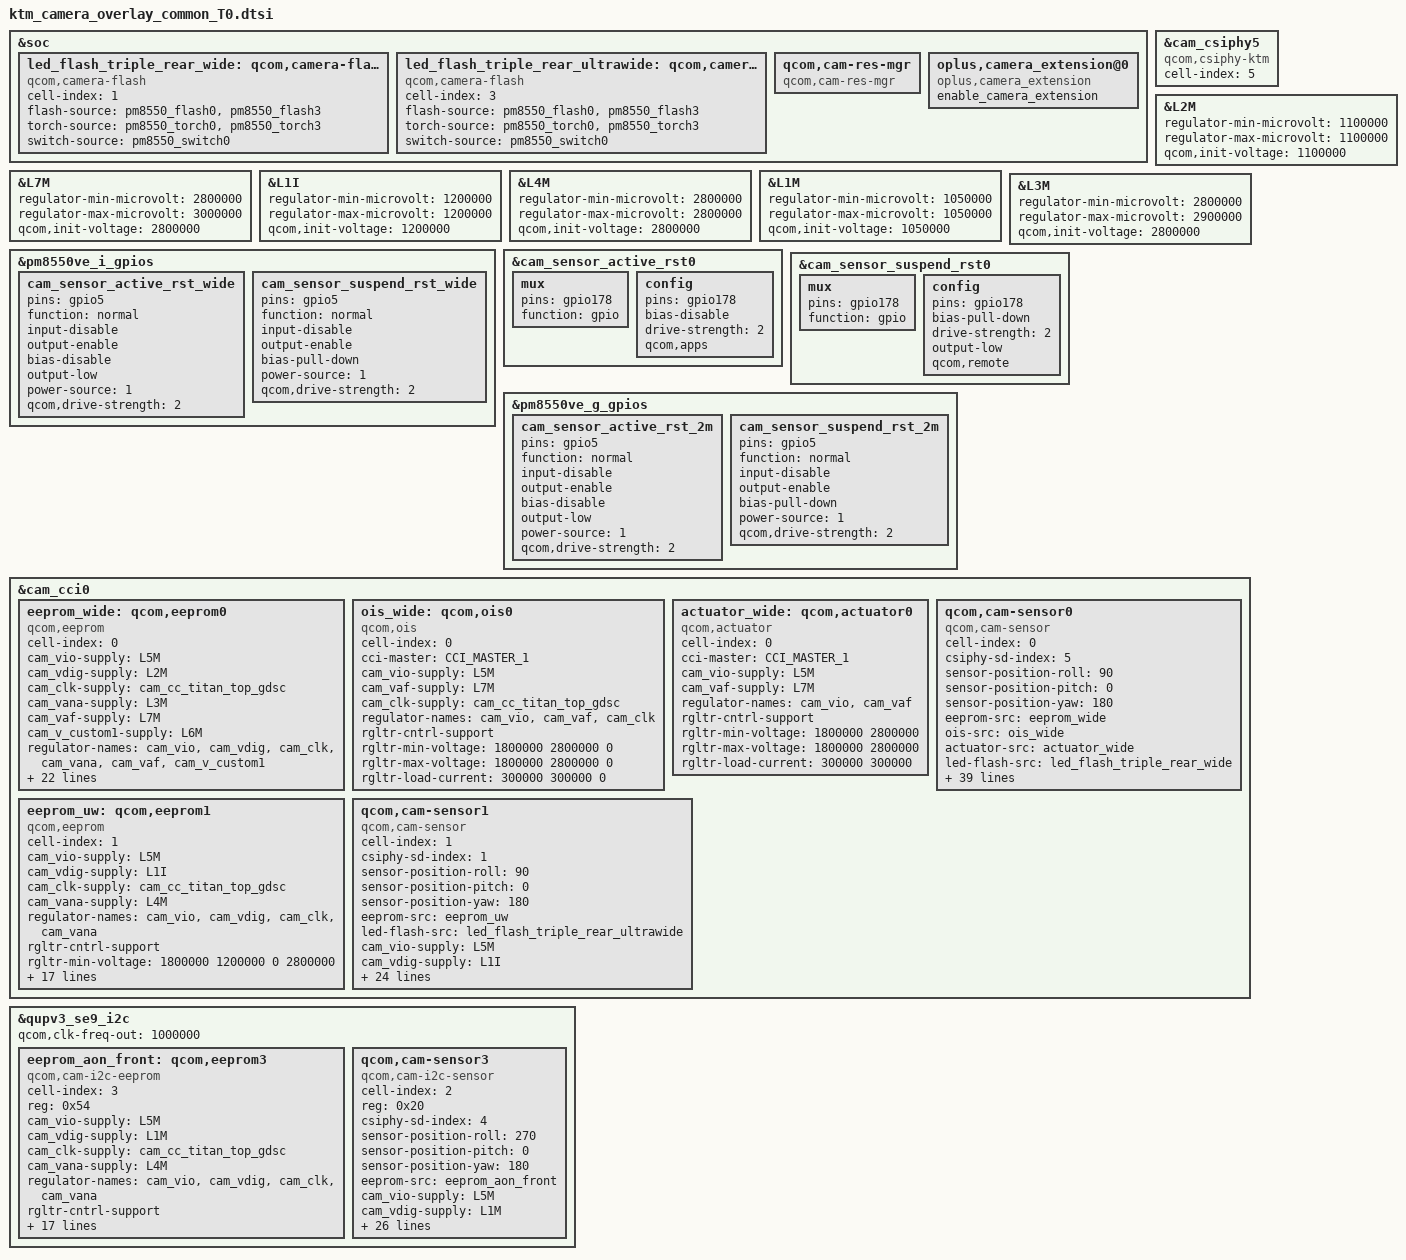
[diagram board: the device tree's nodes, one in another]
#include <dt-bindings/msm-camera.h>
#include "ftm_camera_settings.dtsi"

&soc {
	led_flash_triple_rear_wide: qcom,camera-flash1 {
		cell-index = <1>;
		compatible = "qcom,camera-flash";
		flash-source = <&pm8550_flash0 &pm8550_flash3>;
		torch-source = <&pm8550_torch0 &pm8550_torch3>;
		switch-source = <&pm8550_switch0>;
		status = "ok";
	};

	led_flash_triple_rear_ultrawide: qcom,camera-flash3 {
		cell-index = <3>;
		compatible = "qcom,camera-flash";
		flash-source = <&pm8550_flash0 &pm8550_flash3>;
		torch-source = <&pm8550_torch0 &pm8550_torch3>;
		switch-source = <&pm8550_switch0>;
		status = "ok";
	};

	qcom,cam-res-mgr {
		compatible = "qcom,cam-res-mgr";
		status = "ok";
	};

	oplus,camera_extension@0 {
		compatible = "oplus,camera_extension";
		enable_camera_extension;
		status = "ok";
	};
};

&cam_csiphy5{
	cell-index = <5>;
	compatible = "qcom,csiphy-ktm", "qcom,csiphy";
};

&L2M {
  regulator-min-microvolt = <1100000>;
  regulator-max-microvolt = <1100000>;
  qcom,init-voltage = <1100000>;
};

&L7M {
  regulator-min-microvolt = <2800000>;
  regulator-max-microvolt = <3000000>;
  qcom,init-voltage = <2800000>;
};

&L1I {
  regulator-min-microvolt = <1200000>;
  regulator-max-microvolt = <1200000>;
  qcom,init-voltage = <1200000>;
};

&L4M {
  regulator-min-microvolt = <2800000>;
  regulator-max-microvolt = <2800000>;
  qcom,init-voltage = <2800000>;
};

&L1M {
  regulator-min-microvolt = <1050000>;
  regulator-max-microvolt = <1050000>;
  qcom,init-voltage = <1050000>;
};

&L3M {
  regulator-min-microvolt = <2800000>;
  regulator-max-microvolt = <2900000>;
  qcom,init-voltage = <2800000>;
};


&pm8550ve_i_gpios {
	cam_sensor_active_rst_wide: cam_sensor_active_rst_wide {
		pins = "gpio5";
		function = "normal";
		input-disable;
		output-enable;
		bias-disable;
		output-low;
		power-source = <1>;
		qcom,drive-strength = <2>;
	};

	cam_sensor_suspend_rst_wide: cam_sensor_suspend_rst_wide {
		pins = "gpio5";
		function = "normal";
		input-disable;
		output-enable;
		bias-pull-down;
		power-source = <1>;
		qcom,drive-strength = <2>;
	};
};

&cam_sensor_active_rst0 {
	mux {
		pins = "gpio178";
		function = "gpio";
	};

	config {
		pins = "gpio178";
		bias-disable; /* No PULL */
		drive-strength = <2>; /* 2 MA */
		qcom,apps;
	};
};

&cam_sensor_suspend_rst0 {
	mux {
		pins = "gpio178";
		function = "gpio";
	};

	config {
		pins = "gpio178";
		bias-pull-down; /* PULL DOWN */
		drive-strength = <2>; /* 2 MA */
		output-low;
		qcom,remote;
	};
};

&pm8550ve_g_gpios {
	cam_sensor_active_rst_2m: cam_sensor_active_rst_2m {
		pins = "gpio5";
		function = "normal";
		input-disable;
		output-enable;
		bias-disable;
		output-low;
		power-source = <1>;
		qcom,drive-strength = <2>;
	};

	cam_sensor_suspend_rst_2m: cam_sensor_suspend_rst_2m {
		pins = "gpio5";
		function = "normal";
		input-disable;
		output-enable;
		bias-pull-down;
		power-source = <1>;
		qcom,drive-strength = <2>;
	};
};

&cam_cci0 {

	eeprom_wide: qcom,eeprom0 {
		cell-index = <0>;
		compatible = "qcom,eeprom";
		cam_vio-supply = <&L5M>;
		cam_vdig-supply = <&L2M>;
		cam_clk-supply = <&cam_cc_titan_top_gdsc>;
		cam_vana-supply = <&L3M>;
		cam_vaf-supply = <&L7M>;
		cam_v_custom1-supply = <&L6M>;
		regulator-names = "cam_vio", "cam_vdig", "cam_clk", "cam_vana",
			"cam_vaf", "cam_v_custom1";
		rgltr-cntrl-support;
		rgltr-min-voltage = <1800000 1100000 0 2800000 2800000 1800000>;
		rgltr-max-voltage = <1800000 1100000 0 2800000 2800000 1800000>;
		rgltr-load-current = <300000 1200000 0 300000 300000 300000>;
		gpio-no-mux = <0>;
		pinctrl-names = "cam_default", "cam_suspend";
		pinctrl-0 = <&cam_sensor_mclk1_active
				 &cam_sensor_active_rst_wide>;
		pinctrl-1 = <&cam_sensor_mclk1_suspend
				 &cam_sensor_suspend_rst_wide>;
		gpios = <&tlmm 90 0>,
			<&pm8550ve_i_gpios 5 0>;
		gpio-reset = <1>;
		gpio-req-tbl-num = <0 1>;
		gpio-req-tbl-flags = <1 0>;
		gpio-req-tbl-label = "CAMIF_MCLK1",
					"CAM_RESET1";
		cci-master = <CCI_MASTER_1>;
		clocks = <&cambistmclkcc CAM_BIST_MCLK_CC_MCLK1_CLK>;
		clock-names = "cam_clk";
		clock-cntl-level = "nominal";
		clock-rates = <19200000>;
		status = "ok";
	};

	ois_wide: qcom,ois0 {
		cell-index = <0>;
		compatible = "qcom,ois";
		cci-master = <CCI_MASTER_1>;
		cam_vio-supply = <&L5M>;
		cam_vaf-supply = <&L7M>;
		cam_clk-supply = <&cam_cc_titan_top_gdsc>;
		regulator-names = "cam_vio","cam_vaf", "cam_clk";
		rgltr-cntrl-support;
		rgltr-min-voltage = <1800000 2800000 0>;
		rgltr-max-voltage = <1800000 2800000 0>;
		rgltr-load-current = <300000 300000 0>;
		// ois_gyro,position=<3>;
		// ois_gyro,type=<3>;
		// ois,type=<0>;
		// //ois,name="bu63169";//??
		// ois_module,vendor=<1>;
		// ois_actuator,vednor=<2>;
		// ois,fw=<1>;
		status = "ok";
	};

	actuator_wide: qcom,actuator0 {
		cell-index = <0>;
		compatible = "qcom,actuator";
		cci-master = <CCI_MASTER_1>;
		cam_vio-supply = <&L5M>;
		cam_vaf-supply = <&L7M>;
		regulator-names = "cam_vio", "cam_vaf";
		rgltr-cntrl-support;
		rgltr-min-voltage = <1800000 2800000>;
		rgltr-max-voltage = <1800000 2800000>;
		rgltr-load-current = <300000 300000>;
		// reactive-ctrl-support;
		// //                       reg_addr   addr_type   reg_data    data_type   delay       data_mask
		// reactive-reg-setting = < 0x02       1           0x00        1           2800        0x00 >;
		// is_update_pid;
		// actuator,name = "ak7316";
		// actuator_function = <1>;
		// cci_client_sid = <0x18>;
		// sds-lock-support;
		// //                       reg_addr   addr_type   reg_data    data_type   delay       data_mask
		// sds-lock-reg-setting = < 0x02           1         0x40        1          10            0x00 >,
		//                        < 0x02           1         0x40        1          10            0x00 >,
		//                        < 0x00           1         0x80        1          5             0x00 >,
		//                        < 0x02           1         0x00        1          5             0x00 >;
		status = "ok";
	};

	// wide camera
	qcom,cam-sensor0 {
		cell-index = <0>;
		compatible = "qcom,cam-sensor";
		csiphy-sd-index = <5>;
		sensor-position-roll = <90>;
		sensor-position-pitch = <0>;
		sensor-position-yaw = <180>;
		eeprom-src = <&eeprom_wide>;
		ois-src = <&ois_wide>;
		actuator-src = <&actuator_wide>;
		led-flash-src = <&led_flash_triple_rear_wide>;
		cam_vio-supply = <&L5M>;
		cam_vdig-supply = <&L2M>;
		cam_clk-supply = <&cam_cc_titan_top_gdsc>;
		cam_vana-supply = <&L3M>;
		cam_vaf-supply = <&L7M>;
		cam_v_custom1-supply = <&L6M>;
		regulator-names = "cam_vio", "cam_vdig", "cam_clk", "cam_vana",
			"cam_vaf", "cam_v_custom1";
		rgltr-cntrl-support;
		rgltr-min-voltage = <1800000 1100000 0 2800000 2800000 1800000>;
		rgltr-max-voltage = <1800000 1100000 0 2800000 2800000 1800000>;
		rgltr-load-current = <300000 1200000 0 300000 300000 300000>;
		gpio-no-mux = <0>;
		pinctrl-names = "cam_default", "cam_suspend";
		pinctrl-0 = <&cam_sensor_mclk1_active
				&cam_sensor_active_rst_wide>;
		pinctrl-1 = <&cam_sensor_mclk1_suspend
				&cam_sensor_suspend_rst_wide>;
		gpios = <&tlmm 90 0>,
			<&pm8550ve_i_gpios 5 0>;
		gpio-reset = <1>;
		gpio-req-tbl-num = <0 1>;
		gpio-req-tbl-flags = <1 0>;
		gpio-req-tbl-label = "CAMIF_MCLK1",
					"CAM_RESET1";
		cci-master = <CCI_MASTER_1>;
		clocks = <&cambistmclkcc CAM_BIST_MCLK_CC_MCLK1_CLK>;
		clock-names = "cam_clk";
		clock-cntl-level = "nominal";
		clock-rates = <19200000>;
		//is-support-laser = <1>;
		enable_qsc_write_in_advance = <1>;
		qsc_reg_addr = <0x2210>;
		eeprom_slave_addr = <0xA0>;
		qsc_data_size = <3072>;
		write_qsc_addr = <0x1000>;
		//sensor_setting_id = <13>;
		ftm_setting_compatible = <'R' 0x0016 2 2 0x0906>; // expect camera_0016_0906
		vsync_enable_reg_addr = <0x3051>;
		vsync_enable = <1>;
		vsync_disable = <0>;
		status = "ok";
	};

	eeprom_uw: qcom,eeprom1 {
		cell-index = <1>;
		compatible = "qcom,eeprom";
		cam_vio-supply = <&L5M>;
		cam_vdig-supply = <&L1I>;
		cam_clk-supply = <&cam_cc_titan_top_gdsc>;
		cam_vana-supply = <&L4M>;
		regulator-names = "cam_vio", "cam_vdig","cam_clk", "cam_vana";
		rgltr-cntrl-support;
		rgltr-min-voltage = <1800000 1200000 0 2800000>;
		rgltr-max-voltage = <1800000 1200000 0 2800000>;
		rgltr-load-current = <300000 1200000 0 300000>;
		gpio-no-mux = <0>;
		pinctrl-names = "cam_default", "cam_suspend";
		pinctrl-0 = <&cam_sensor_mclk0_active
				&cam_sensor_active_rst0>;
		pinctrl-1 = <&cam_sensor_mclk0_suspend
				&cam_sensor_suspend_rst0>;
		gpios = <&tlmm 89 0>,
			<&tlmm 178 0>;
		gpio-reset = <1>;
		gpio-req-tbl-num = <0 1>;
		gpio-req-tbl-flags = <1 0>;
		gpio-req-tbl-label = "CAMIF_MCLK0",
					"CAM_RESET0";
		cci-master = <CCI_MASTER_0>;
		clocks = <&cambistmclkcc CAM_BIST_MCLK_CC_MCLK0_CLK>;
		clock-names = "cam_clk";
		clock-cntl-level = "nominal";
		clock-rates = <19200000>;
		status = "ok";
	};

	// ultrawide camera
	qcom,cam-sensor1 {
		cell-index = <1>;
		compatible = "qcom,cam-sensor";
		csiphy-sd-index = <1>;
		sensor-position-roll = <90>;
		sensor-position-pitch = <0>;
		sensor-position-yaw = <180>;
		eeprom-src = <&eeprom_uw>;
		led-flash-src = <&led_flash_triple_rear_ultrawide>;
		cam_vio-supply = <&L5M>;
		cam_vdig-supply = <&L1I>;
		cam_clk-supply = <&cam_cc_titan_top_gdsc>;
		cam_vana-supply = <&L4M>;
		regulator-names = "cam_vio", "cam_vdig","cam_clk", "cam_vana";
		rgltr-cntrl-support;
		rgltr-min-voltage = <1800000 1200000 0 2800000>;
		rgltr-max-voltage = <1800000 1200000 0 2800000>;
		rgltr-load-current = <300000 1200000 0 300000>;
		gpio-no-mux = <0>;
		pinctrl-names = "cam_default", "cam_suspend";
		pinctrl-0 = <&cam_sensor_mclk0_active
				&cam_sensor_active_rst0>;
		pinctrl-1 = <&cam_sensor_mclk0_suspend
				&cam_sensor_suspend_rst0>;
		gpios = <&tlmm 89 0>,
			<&tlmm 178 0>;
		gpio-reset = <1>;
		gpio-req-tbl-num = <0 1>;
		gpio-req-tbl-flags = <1 0>;
		gpio-req-tbl-label = "CAMIF_MCLK0",
					"CAM_RESET0";
		cci-master = <CCI_MASTER_0>;
		clocks = <&cambistmclkcc CAM_BIST_MCLK_CC_MCLK0_CLK>;
		clock-names = "cam_clk";
		clock-cntl-level = "nominal";
		clock-rates = <19200000>;
		ftm_setting_compatible = <'R' 0x0000 1 2 0x5608>; // expect camera_0000_5608
		status = "ok";
	};


};

&qupv3_se9_i2c {
	status = "ok";
	// qcom,high-perf;
	qcom,clk-freq-out = <1000000>;
	// qcom,pm-ctrl-client;

	eeprom_aon_front: qcom,eeprom3 {
		cell-index = <3>;
		reg = <0x54>;
		compatible = "qcom,cam-i2c-eeprom";
		cam_vio-supply = <&L5M>;
		cam_vdig-supply = <&L1M>;
		cam_clk-supply = <&cam_cc_titan_top_gdsc>;
		cam_vana-supply = <&L4M>;
		regulator-names = "cam_vio", "cam_vdig","cam_clk", "cam_vana";
		rgltr-cntrl-support;
		rgltr-min-voltage = <1800000 1050000 0 2800000>;
		rgltr-max-voltage = <1800000 1050000 0 2800000>;
		rgltr-load-current = <300000 600000 0  300000>;
		gpio-no-mux = <0>;
		pinctrl-names = "cam_default", "cam_suspend";
		pinctrl-0 = <&cam_sensor_mclk4_active
				 &cam_sensor_active_rst4>;
		pinctrl-1 = <&cam_sensor_mclk4_suspend
				 &cam_sensor_suspend_rst4>;
		gpios = <&tlmm 93 0>,
			<&tlmm 7 0>;
		gpio-reset = <1>;
		gpio-req-tbl-num = <0 1>;
		gpio-req-tbl-flags = <1 0>;
		gpio-req-tbl-label = "CAMIF_MCLK4",
					"CAM_RESET4";
		clocks = <&cambistmclkcc CAM_BIST_MCLK_CC_MCLK4_CLK>;
		clock-names = "cam_clk";
		clock-cntl-level = "nominal";
		clock-rates = <19200000>;
		status = "ok";
	};

	// front camera
	qcom,cam-sensor3 {
		cell-index = <2>;
		reg = <0x20>;
		compatible = "qcom,cam-i2c-sensor";
		csiphy-sd-index = <4>;
		sensor-position-roll = <270>;
		sensor-position-pitch = <0>;
		sensor-position-yaw = <180>;
		eeprom-src = <&eeprom_aon_front>;
		cam_vio-supply = <&L5M>;
		cam_vdig-supply = <&L1M>;
		cam_clk-supply = <&cam_cc_titan_top_gdsc>;
		cam_vana-supply = <&L4M>;
		regulator-names = "cam_vio", "cam_vdig","cam_clk", "cam_vana";
		rgltr-cntrl-support;
		aon-camera-id = <AON_CAM1>;
		rgltr-min-voltage = <1800000 1050000 0 2800000>;
		rgltr-max-voltage = <1800000 1050000 0 2800000>;
		rgltr-load-current = <300000 600000 0  300000>;
		gpio-no-mux = <0>;
		pinctrl-names = "cam_default", "cam_suspend";
		pinctrl-0 = <&cam_sensor_mclk4_active
				 &cam_sensor_active_rst4>;
		pinctrl-1 = <&cam_sensor_mclk4_suspend
				 &cam_sensor_suspend_rst4>;
		gpios = <&tlmm 93 0>,
			<&tlmm 7 0>;
		gpio-reset = <1>;
		gpio-req-tbl-num = <0 1>;
		gpio-req-tbl-flags = <1 0>;
		gpio-req-tbl-label = "CAMIF_MCLK4",
					"CAM_RESET4";
		clocks = <&cambistmclkcc CAM_BIST_MCLK_CC_MCLK4_CLK>;
		clock-names = "cam_clk";
		clock-cntl-level = "nominal";
		clock-rates = <19200000>;
		swremosaic_sensor_id = <0x0471>;
		ftm_setting_compatible = <'R' 0x0016 2 2 0x0615
					  'R' 0x0016 2 2 0x0471
					  'W' 0x0A02 2 1 0x7F
					  'W' 0x0A00 2 1 0x01
					  'R' 0x0A1F 2 1 0x00B4>; // expect camera_0016_0615_0A1F_0034 camera_0016_0615_0A1F_0038 or camera_0016_0615_0A1F_00B4 camera_0016_0471_0A1F_0000
		status = "ok";
	};

};

